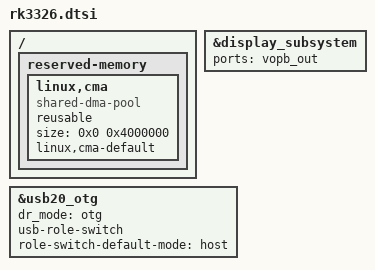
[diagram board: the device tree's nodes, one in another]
// SPDX-License-Identifier: (GPL-2.0+ OR MIT)
/*
 * Copyright (c) 2020 Fuzhou Rockchip Electronics Co., Ltd
 */

#include "px30.dtsi"

/ {
	reserved-memory {
		#address-cells = <2>;
		#size-cells = <2>;
		ranges;

		linux,cma {
			compatible = "shared-dma-pool";
			reusable;
			size = <0x0 0x4000000>;	/* 64 MiB */
			linux,cma-default;
		};
	};
};

&display_subsystem {
	ports = <&vopb_out>;
};

/delete-node/ &dsi_in_vopl;
/delete-node/ &lvds_vopl_in;
/delete-node/ &vopl;
/delete-node/ &vopl_mmu;

&usb20_otg {
	dr_mode = "otg";
	usb-role-switch;
	role-switch-default-mode = "host";
};
